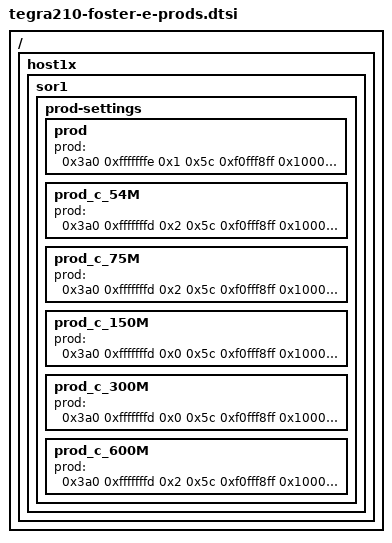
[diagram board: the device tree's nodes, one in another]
/*
 * Copyright (c) 2014, NVIDIA CORPORATION.  All rights reserved.
 *
 * This program is free software; you can redistribute it and/or modify
 * it under the terms of the GNU General Public License as published by
 * the Free Software Foundation; version 2 of the License.
 *
 * This program is distributed in the hope that it will be useful, but WITHOUT
 * ANY WARRANTY; without even the implied warranty of MERCHANTABILITY or
 * FITNESS FOR A PARTICULAR PURPOSE.  See the GNU General Public License for
 * more details.
 *
 * You should have received a copy of the GNU General Public License along
 * with this program; if not, write to the Free Software Foundation, Inc.,
 * 51 Franklin Street, Fifth Floor, Boston, MA  02110-1301, USA.
 *
 */

/ {
	host1x {
		sor1 {
			prod-settings {
				prod {
					prod = <0x3a0 0xfffffffe 0x1
					0x5c 0xf0fff8ff 0x1000000
					0x60 0xff0fe0ff 0x300f80
					0x68 0xf0ffffff 0xE000000
					0x138 0x0 0x3C3C3C3C
					0x148 0x0 0x3F3F3F3F
					0x170 0xffbf00ff 0x401000>;
				};

				prod_c_54M {
					prod = <0x3a0 0xfffffffd 0x2
					0x5c 0xf0fff8ff 0x1000000
					0x60 0xff0fe0ff 0x300f80
					0x68 0xf0ffffff 0xE000000
					0x138 0x0 0x3C3C3C3C
					0x148 0x0 0x3F3F3F3F
					0x170 0xffbf00ff 0x401000>;
				};

				prod_c_75M {
					prod = <0x3a0 0xfffffffd 0x2
					0x5c 0xf0fff8ff 0x1000100
					0x60 0xff0fe0ff 0x300f80
					0x68 0xf0ffffff 0xE000000
					0x138 0x0 0x3C3C3C3C
					0x148 0x0 0x3F3F3F3F
					0x170 0xffbf00ff 0x404000>;
				};

				prod_c_150M {
					prod = <0x3a0 0xfffffffd 0x0
					0x5c 0xf0fff8ff 0x1000300
					0x60 0xff0fe0ff 0x300980
					0x68 0xf0ffffff 0xE000000
					0x138 0x0 0x3C3C3C3C
					0x148 0x0 0x3F3F3F3F
					0x170 0xffbf00ff 0x406600>;
				};

				prod_c_300M {
					prod = <0x3a0 0xfffffffd 0x0
					0x5c 0xf0fff8ff 0x1000300
					0x60 0xff0fe0ff 0x300980
					0x68 0xf0ffffff 0xE000000
					0x138 0x0 0x3C3C3C3C
					0x148 0x0 0x3F3F3F3F
					0x170 0xffbf00ff 0x406600>;
				};

				prod_c_600M {
					prod = <0x3a0 0xfffffffd 0x2
					0x5c 0xf0fff8ff 0x1000300
					0x60 0xff0fe0ff 0x301F80
					0x68 0xf0ffffff 0xE000000
					0x138 0x0 0x3E3E3E3E
					0x148 0x0 0x0C0C0C0C
					0x170 0xffbf00ff 0x406600>;
				};
			};
		};
	};
};
